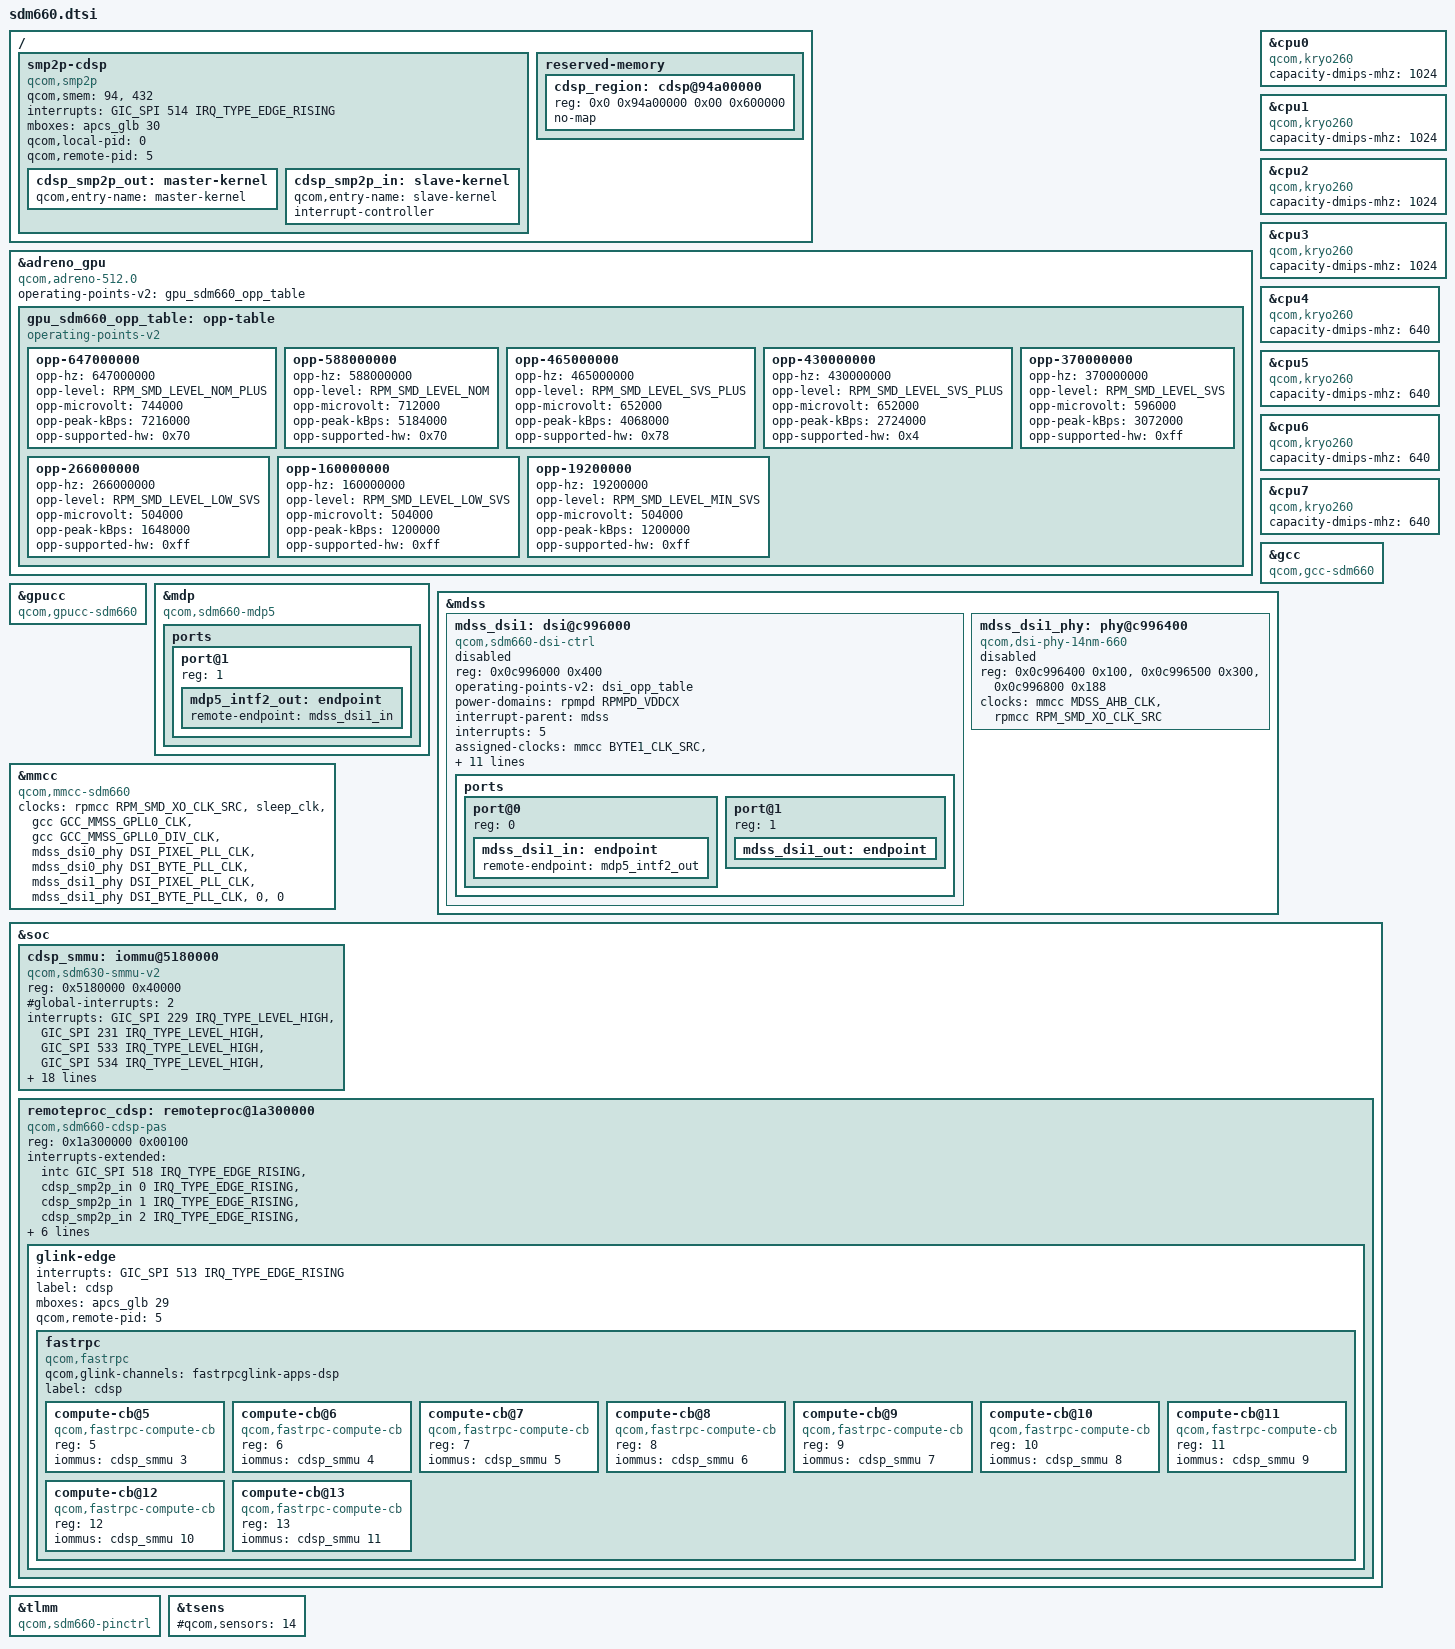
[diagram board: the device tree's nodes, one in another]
// SPDX-License-Identifier: GPL-2.0-only
/*
 * Copyright (c) 2018, Craig Tatlor.
 * Copyright (c) 2020, Alexey Minnekhanov <alexey.min@gmail.com>
 * Copyright (c) 2020, AngeloGioacchino Del Regno <kholk11@gmail.com>
 * Copyright (c) 2020, Konrad Dybcio <konradybcio@gmail.com>
 * Copyright (c) 2020, Martin Botka <martin.botka1@gmail.com>
 */

#include "sdm630.dtsi"

/delete-node/ &buffer_mem;

/ {
	smp2p-cdsp {
		compatible = "qcom,smp2p";
		qcom,smem = <94>, <432>;
		interrupts = <GIC_SPI 514 IRQ_TYPE_EDGE_RISING>;
		mboxes = <&apcs_glb 30>;
		qcom,local-pid = <0>;
		qcom,remote-pid = <5>;

		cdsp_smp2p_out: master-kernel {
			qcom,entry-name = "master-kernel";
			#qcom,smem-state-cells = <1>;
		};

		cdsp_smp2p_in: slave-kernel {
			qcom,entry-name = "slave-kernel";
			interrupt-controller;
			#interrupt-cells = <2>;
		};
	};

	reserved-memory {
		cdsp_region: cdsp@94a00000 {
			reg = <0x0 0x94a00000 0x00 0x600000>;
			no-map;
		};
	};
};

&adreno_gpu {
	compatible = "qcom,adreno-512.0", "qcom,adreno";
	operating-points-v2 = <&gpu_sdm660_opp_table>;

	/*
	 * Delete the whole OPP table inherited from SDM630 - we need to
	 * rewrite it cleanly from scratch, because frequency tables in gpucc
	 * are different between sdm630 - sdm660, and the same bin (135) has
	 * different meaning (unlocks different frequencies) on sdm660,
	 * compared to sdm630.
	 */
	/delete-node/ opp-table;

	gpu_sdm660_opp_table: opp-table {
		compatible = "operating-points-v2";

		/*
		 * Per-OPP voltages (opp-microvolt) are the MMSS/GFX CPR4
		 * corner *floor* voltages taken verbatim from the stock R11T
		 * DTB, node cpr4-ctrl@05061000 (compatible
		 * "qcom,cpr4-sdm660-mmss-ldo-regulator"), thread@0/regulator
		 * property qcom,cpr-voltage-floor:
		 *
		 *   <0x7b0c0 0x7b0c0 0x91820 0x9f2e0 0xadd40 0xb5a40 0x1053b0>
		 *   = 504000 504000 596000 652000 712000 744000 1070000 uV
		 *     @ 160    266    370    465    588    647    750 MHz
		 *
		 * They are supplied for one reason only: the Adreno a5xx
		 * GPMU/AGC init reads the OPP voltage via _get_mvolts()
		 * (a5xx_power.c) to program AGC_MSG_PAYLOAD(2).  Without
		 * opp-microvolt that call returned 0 mV for every level,
		 * leaving the GPU power-management block with a bogus
		 * voltage reference.  The values are *not* used to drive a
		 * regulator: the GFX rail is an open-loop bypassed LDO in
		 * both stock and mainline (stock sets
		 * qcom,cpr-corner-allow-ldo-mode = <0>, mainline
		 * qcom-gfx-ldo.c sets bypass = true), and the actual GPU
		 * corner voltage is delivered as an RPM VDD_CX vote through
		 * the opp-level below.
		 *
		 * The 750 MHz corner floor (1070000 uV) is listed above for
		 * completeness only; its OPP is commented out further down.
		 */

		/*
		 * 750 MHz is only available on the highest speed bin
		 * Though it cannot be used for now due to interconnect
		 * framework not supporting multiple frequencies
		 * at the same opp-level.
		 * These OPPs are correct, but we are lacking support for the
		 * GPU regulator. Hence, disable them for now to prevent the
		 * platform from hanging on high graphics loads.

		 * bin 157 -> bit 6 *
		opp-750000000 {
			opp-hz = /bits/ 64 <750000000>;
			opp-level = <RPM_SMD_LEVEL_TURBO>;
			opp-peak-kBps = <5412000>;
			opp-supported-hw = <0x40>;
		}; */

		/* bins 157,146 -> bits 6,5 */
		/*opp-700000000 {
			opp-hz = /bits/ 64 <700000000>;
			opp-level = <RPM_SMD_LEVEL_TURBO>;
			opp-peak-kBps = <5184000>;
			opp-supported-hw = <0x60>;
		};*/

		/* bins 157,146,135 -> bits 6,5,4 */
		opp-647000000 {
			opp-hz = /bits/ 64 <647000000>;
			opp-level = <RPM_SMD_LEVEL_NOM_PLUS>;
			opp-microvolt = <744000>;
			opp-peak-kBps = <7216000>;
			opp-supported-hw = <0x70>;
		};

		/*
		 * The opp-peak-kBps values below are the GPU->EBI peak
		 * bandwidth votes of the stock firmware (kgsl
		 * qcom,gpu-pwrlevel-bins -> qcom,bus-freq index into the
		 * qcom,msm-bus,vectors-KBps table):
		 *
		 *   588 MHz -> level 10 = 5184000
		 *   465 MHz -> level  9 = 4068000
		 *   370 MHz -> level  8 = 3072000
		 *   266 MHz -> level  3 =  800000   (ours is higher, keep)
		 *   160 MHz -> level  3 =  800000   (ours is higher, keep)
		 *
		 * The inherited values sit exactly two table entries too low
		 * for every level from 370 MHz upwards:
		 *
		 *   588 MHz: ours level  8, stock level 10
		 *   465 MHz: ours level  7, stock level  9
		 *   370 MHz: ours level  6, stock level  8
		 *
		 * i.e. the 588 MHz OPP asked for exactly the peak bandwidth the
		 * stock firmware reserves for 370 MHz, leaving the GPU up to
		 * 40% short of its stock memory bandwidth at its highest
		 * operating point.  Only the under-voted levels are changed.
		 *
		 * 647 MHz follows a different rule: it is the *top* pwrlevel of
		 * speed bin 135 (this unit), and the stock firmware gives the
		 * top pwrlevel the maximum bus vote (bus-freq = <0x0d> =
		 * level 13 = 7216000, bus-min = level 12 = 6220000), whereas
		 * 647 MHz uses level 11 = 5412000 on the bins where it is not
		 * the top.  Use the bin 135 value so the GPU is never short of
		 * its stock memory bandwidth at 647 MHz.  The inherited value
		 * (level 9 = 4068000) was even below the 588 MHz vote.
		 */

		/* bins 157,146,135 -> bits 6,5,4 */
		opp-588000000 {
			opp-hz = /bits/ 64 <588000000>;
			opp-level = <RPM_SMD_LEVEL_NOM>;
			opp-microvolt = <712000>;
			opp-peak-kBps = <5184000>;
			opp-supported-hw = <0x70>;
		};

		/* bins 157,146,135,122 -> bits 6,5,4,3 */
		opp-465000000 {
			opp-hz = /bits/ 64 <465000000>;
			opp-level = <RPM_SMD_LEVEL_SVS_PLUS>;
			opp-microvolt = <652000>;
			opp-peak-kBps = <4068000>;
			opp-supported-hw = <0x78>;
		};

		/* this one is for SDM636 with bin 90, bit 2.
		 * 430 MHz is not in the SDM660 GFX CPR4 corner table (the
		 * table steps 370 -> 465), so it carries the 465 MHz corner
		 * floor: it must not be *under* the corner it runs in. */
		opp-430000000 {
			opp-hz = /bits/ 64 <430000000>;
			opp-level = <RPM_SMD_LEVEL_SVS_PLUS>;
			opp-microvolt = <652000>;
			opp-peak-kBps = <2724000>;
			opp-supported-hw = <0x4>;
		};

		/* 370 MHz and below are supported in all bins */
		opp-370000000 {
			opp-hz = /bits/ 64 <370000000>;
			opp-level = <RPM_SMD_LEVEL_SVS>;
			opp-microvolt = <596000>;
			opp-peak-kBps = <3072000>;
			opp-supported-hw = <0xff>;
		};

		opp-266000000 {
			opp-hz = /bits/ 64 <266000000>;
			opp-level = <RPM_SMD_LEVEL_LOW_SVS>;
			opp-microvolt = <504000>;
			opp-peak-kBps = <1648000>;
			opp-supported-hw = <0xff>;
		};

		/*
		 * 160 MHz: the stock MMSS/GFX CPR4 table lists corner 0
		 * (160 MHz) with qcom,system-voltage = <0x40>, i.e.
		 * RPM_SMD_LEVEL_LOW_SVS (64), not MIN_SVS.  Match the
		 * vendor corner so the low end is not under-voted.
		 */
		opp-160000000 {
			opp-hz = /bits/ 64 <160000000>;
			opp-level = <RPM_SMD_LEVEL_LOW_SVS>;
			opp-microvolt = <504000>;
			opp-peak-kBps = <1200000>;
			opp-supported-hw = <0xff>;
		};

		/* Idle, parented to gpucc_cxo.  Not present in the stock
		 * CPR4 corner table (which starts at 160 MHz); keep the
		 * TOPS-1 floor voltage to be consistent with the rail. */
		opp-19200000 {
			opp-hz = /bits/ 64 <19200000>;
			opp-level = <RPM_SMD_LEVEL_MIN_SVS>;
			opp-microvolt = <504000>;
			opp-peak-kBps = <1200000>;
			opp-supported-hw = <0xff>;
		};
	};
};

&cpu0 {
	compatible = "qcom,kryo260";
	capacity-dmips-mhz = <1024>;
	/delete-property/ operating-points-v2;
};

&cpu1 {
	compatible = "qcom,kryo260";
	capacity-dmips-mhz = <1024>;
	/delete-property/ operating-points-v2;
};

&cpu2 {
	compatible = "qcom,kryo260";
	capacity-dmips-mhz = <1024>;
	/delete-property/ operating-points-v2;
};

&cpu3 {
	compatible = "qcom,kryo260";
	capacity-dmips-mhz = <1024>;
	/delete-property/ operating-points-v2;
};

&cpu4 {
	compatible = "qcom,kryo260";
	capacity-dmips-mhz = <640>;
	/delete-property/ operating-points-v2;
};

&cpu5 {
	compatible = "qcom,kryo260";
	capacity-dmips-mhz = <640>;
	/delete-property/ operating-points-v2;
};

&cpu6 {
	compatible = "qcom,kryo260";
	capacity-dmips-mhz = <640>;
	/delete-property/ operating-points-v2;
};

&cpu7 {
	compatible = "qcom,kryo260";
	capacity-dmips-mhz = <640>;
	/delete-property/ operating-points-v2;
};

&gcc {
	compatible = "qcom,gcc-sdm660";
};

&gpucc {
	compatible = "qcom,gpucc-sdm660";
};

&mdp {
	compatible = "qcom,sdm660-mdp5", "qcom,mdp5";

	ports {
		port@1 {
			reg = <1>;
			mdp5_intf2_out: endpoint {
				remote-endpoint = <&mdss_dsi1_in>;
			};
		};
	};
};

&mdss {
	mdss_dsi1: dsi@c996000 {
		compatible = "qcom,sdm660-dsi-ctrl",
			     "qcom,mdss-dsi-ctrl";
		reg = <0x0c996000 0x400>;
		reg-names = "dsi_ctrl";

		/* DSI1 shares the OPP table with DSI0 */
		operating-points-v2 = <&dsi_opp_table>;
		power-domains = <&rpmpd RPMPD_VDDCX>;

		interrupt-parent = <&mdss>;
		interrupts = <5>;

		assigned-clocks = <&mmcc BYTE1_CLK_SRC>,
					<&mmcc PCLK1_CLK_SRC>;
		assigned-clock-parents = <&mdss_dsi1_phy DSI_BYTE_PLL_CLK>,
					 <&mdss_dsi1_phy DSI_PIXEL_PLL_CLK>;

		clocks = <&mmcc MDSS_MDP_CLK>,
				<&mmcc MDSS_BYTE1_CLK>,
				<&mmcc MDSS_BYTE1_INTF_CLK>,
				<&mmcc MNOC_AHB_CLK>,
				<&mmcc MDSS_AHB_CLK>,
				<&mmcc MDSS_AXI_CLK>,
				<&mmcc MISC_AHB_CLK>,
				<&mmcc MDSS_PCLK1_CLK>,
				<&mmcc MDSS_ESC1_CLK>;
		clock-names = "mdp_core",
					"byte",
					"byte_intf",
					"mnoc",
					"iface",
					"bus",
					"core_mmss",
					"pixel",
					"core";

		phys = <&mdss_dsi1_phy>;

		status = "disabled";

		ports {
			#address-cells = <1>;
			#size-cells = <0>;

			port@0 {
				reg = <0>;
				mdss_dsi1_in: endpoint {
					remote-endpoint = <&mdp5_intf2_out>;
				};
			};

			port@1 {
				reg = <1>;
				mdss_dsi1_out: endpoint {
				};
			};
		};
	};

	mdss_dsi1_phy: phy@c996400 {
		compatible = "qcom,dsi-phy-14nm-660";
		reg = <0x0c996400 0x100>,
				<0x0c996500 0x300>,
				<0x0c996800 0x188>;
		reg-names = "dsi_phy",
				"dsi_phy_lane",
				"dsi_pll";

		#clock-cells = <1>;
		#phy-cells = <0>;

		clocks = <&mmcc MDSS_AHB_CLK>, <&rpmcc RPM_SMD_XO_CLK_SRC>;
		clock-names = "iface", "ref";
		status = "disabled";
	};
};

&mmcc {
	compatible = "qcom,mmcc-sdm660";
	clocks = <&rpmcc RPM_SMD_XO_CLK_SRC>,
			<&sleep_clk>,
			<&gcc GCC_MMSS_GPLL0_CLK>,
			<&gcc GCC_MMSS_GPLL0_DIV_CLK>,
			<&mdss_dsi0_phy DSI_PIXEL_PLL_CLK>,
			<&mdss_dsi0_phy DSI_BYTE_PLL_CLK>,
			<&mdss_dsi1_phy DSI_PIXEL_PLL_CLK>,
			<&mdss_dsi1_phy DSI_BYTE_PLL_CLK>,
			<0>,
			<0>;
};

&soc {
	cdsp_smmu: iommu@5180000 {
		compatible = "qcom,sdm630-smmu-v2", "qcom,smmu-v2";
		reg = <0x5180000 0x40000>;
		#iommu-cells = <1>;

		#global-interrupts = <2>;
		interrupts = <GIC_SPI 229 IRQ_TYPE_LEVEL_HIGH>,
			     <GIC_SPI 231 IRQ_TYPE_LEVEL_HIGH>,
			     <GIC_SPI 533 IRQ_TYPE_LEVEL_HIGH>,
			     <GIC_SPI 534 IRQ_TYPE_LEVEL_HIGH>,
			     <GIC_SPI 535 IRQ_TYPE_LEVEL_HIGH>,
			     <GIC_SPI 536 IRQ_TYPE_LEVEL_HIGH>,
			     <GIC_SPI 537 IRQ_TYPE_LEVEL_HIGH>,
			     <GIC_SPI 538 IRQ_TYPE_LEVEL_HIGH>,
			     <GIC_SPI 539 IRQ_TYPE_LEVEL_HIGH>,
			     <GIC_SPI 540 IRQ_TYPE_LEVEL_HIGH>,
			     <GIC_SPI 541 IRQ_TYPE_LEVEL_HIGH>,
			     <GIC_SPI 542 IRQ_TYPE_LEVEL_HIGH>,
			     <GIC_SPI 543 IRQ_TYPE_LEVEL_HIGH>,
			     <GIC_SPI 544 IRQ_TYPE_LEVEL_HIGH>,
			     <GIC_SPI 545 IRQ_TYPE_LEVEL_HIGH>,
			     <GIC_SPI 546 IRQ_TYPE_LEVEL_HIGH>,
			     <GIC_SPI 547 IRQ_TYPE_LEVEL_HIGH>,
			     <GIC_SPI 548 IRQ_TYPE_LEVEL_HIGH>,
			     <GIC_SPI 549 IRQ_TYPE_LEVEL_HIGH>;

		clocks = <&gcc GCC_HLOS1_VOTE_TURING_ADSP_SMMU_CLK>;
		clock-names = "bus";

		power-domains = <&gcc HLOS1_VOTE_TURING_ADSP_GDSC>;

	};

	remoteproc_cdsp: remoteproc@1a300000 {
		compatible = "qcom,sdm660-cdsp-pas";
		reg = <0x1a300000 0x00100>;
		interrupts-extended = <&intc GIC_SPI 518 IRQ_TYPE_EDGE_RISING>,
				      <&cdsp_smp2p_in 0 IRQ_TYPE_EDGE_RISING>,
				      <&cdsp_smp2p_in 1 IRQ_TYPE_EDGE_RISING>,
				      <&cdsp_smp2p_in 2 IRQ_TYPE_EDGE_RISING>,
				      <&cdsp_smp2p_in 3 IRQ_TYPE_EDGE_RISING>;
		interrupt-names = "wdog",
				  "fatal",
				  "ready",
				  "handover",
				  "stop-ack";

		clocks = <&rpmcc RPM_SMD_XO_CLK_SRC>;
		clock-names = "xo";

		memory-region = <&cdsp_region>;
		power-domains = <&rpmpd SDM660_VDDCX>;
		power-domain-names = "cx";

		qcom,smem-states = <&cdsp_smp2p_out 0>;
		qcom,smem-state-names = "stop";

		glink-edge {
			interrupts = <GIC_SPI 513 IRQ_TYPE_EDGE_RISING>;

			label = "cdsp";
			mboxes = <&apcs_glb 29>;
			qcom,remote-pid = <5>;

			fastrpc {
				compatible = "qcom,fastrpc";
				qcom,glink-channels = "fastrpcglink-apps-dsp";
				label = "cdsp";
				#address-cells = <1>;
				#size-cells = <0>;

				compute-cb@5 {
					compatible = "qcom,fastrpc-compute-cb";
					reg = <5>;
					iommus = <&cdsp_smmu 3>;
				};

				compute-cb@6 {
					compatible = "qcom,fastrpc-compute-cb";
					reg = <6>;
					iommus = <&cdsp_smmu 4>;
				};

				compute-cb@7 {
					compatible = "qcom,fastrpc-compute-cb";
					reg = <7>;
					iommus = <&cdsp_smmu 5>;
				};

				compute-cb@8 {
					compatible = "qcom,fastrpc-compute-cb";
					reg = <8>;
					iommus = <&cdsp_smmu 6>;
				};

				compute-cb@9 {
					compatible = "qcom,fastrpc-compute-cb";
					reg = <9>;
					iommus = <&cdsp_smmu 7>;
				};

				compute-cb@10 {
					compatible = "qcom,fastrpc-compute-cb";
					reg = <10>;
					iommus = <&cdsp_smmu 8>;
				};

				compute-cb@11 {
					compatible = "qcom,fastrpc-compute-cb";
					reg = <11>;
					iommus = <&cdsp_smmu 9>;
				};

				compute-cb@12 {
					compatible = "qcom,fastrpc-compute-cb";
					reg = <12>;
					iommus = <&cdsp_smmu 10>;
				};

				compute-cb@13 {
					compatible = "qcom,fastrpc-compute-cb";
					reg = <13>;
					iommus = <&cdsp_smmu 11>;
				};
			};
		};
	};
};

&tlmm {
	compatible = "qcom,sdm660-pinctrl";
};

&tsens {
	#qcom,sensors = <14>;
};
